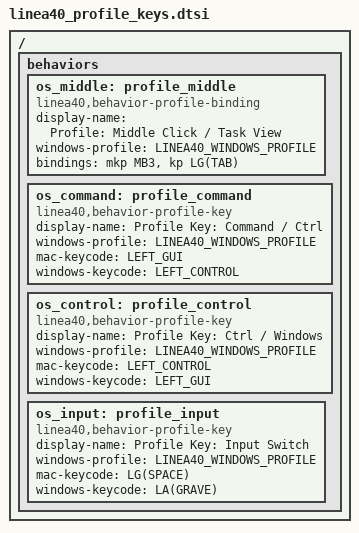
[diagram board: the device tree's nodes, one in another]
#include <dt-bindings/zmk/keys.h>
#include <dt-bindings/zmk/pointing.h>

#ifndef LINEA40_WINDOWS_PROFILE
#define LINEA40_WINDOWS_PROFILE 1
#endif

/ {
    behaviors {
        os_middle: profile_middle {
            compatible = "linea40,behavior-profile-binding";
            #binding-cells = <0>;
            display-name = "Profile: Middle Click / Task View";
            windows-profile = <LINEA40_WINDOWS_PROFILE>;
            bindings = <&mkp MB3>, <&kp LG(TAB)>;
        };

        os_command: profile_command {
            compatible = "linea40,behavior-profile-key";
            #binding-cells = <0>;
            display-name = "Profile Key: Command / Ctrl";
            windows-profile = <LINEA40_WINDOWS_PROFILE>;
            mac-keycode = <LEFT_GUI>;
            windows-keycode = <LEFT_CONTROL>;
        };

        os_control: profile_control {
            compatible = "linea40,behavior-profile-key";
            #binding-cells = <0>;
            display-name = "Profile Key: Ctrl / Windows";
            windows-profile = <LINEA40_WINDOWS_PROFILE>;
            mac-keycode = <LEFT_CONTROL>;
            windows-keycode = <LEFT_GUI>;
        };

        os_input: profile_input {
            compatible = "linea40,behavior-profile-key";
            #binding-cells = <0>;
            display-name = "Profile Key: Input Switch";
            windows-profile = <LINEA40_WINDOWS_PROFILE>;
            mac-keycode = <LG(SPACE)>;
            windows-keycode = <LA(GRAVE)>;
        };
    };
};
